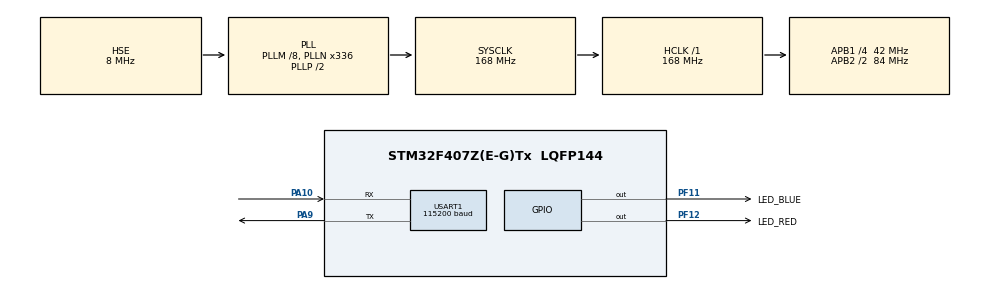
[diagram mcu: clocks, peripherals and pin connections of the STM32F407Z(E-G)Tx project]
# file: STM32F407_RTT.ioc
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Mcu.Family=STM32F4
Mcu.Name=STM32F407Z(E-G)Tx
Mcu.Package=LQFP144
NVIC.PriorityGroup=NVIC_PRIORITYGROUP_4
PA10.GPIO_PuPd=GPIO_PULLUP
PA10.Mode=Asynchronous
PA10.Signal=USART1_RX
PA13.Mode=Serial_Wire
PA13.Signal=SYS_JTMS-SWDIO
PA14.Mode=Serial_Wire
PA14.Signal=SYS_JTCK-SWCLK
PA9.GPIO_PuPd=GPIO_PULLUP
PA9.Mode=Asynchronous
PA9.Signal=USART1_TX
PC14-OSC32_IN.Mode=LSE-External-Oscillator
PC14-OSC32_IN.Signal=RCC_OSC32_IN
PC15-OSC32_OUT.Mode=LSE-External-Oscillator
PC15-OSC32_OUT.Signal=RCC_OSC32_OUT
PH0-OSC_IN.Mode=HSE-External-Oscillator
PH0-OSC_IN.Signal=RCC_OSC_IN
PH1-OSC_OUT.Mode=HSE-External-Oscillator
PH1-OSC_OUT.Signal=RCC_OSC_OUT
PF11.GPIO_Label=LED_BLUE
PF11.Signal=GPIO_Output
PF12.GPIO_Label=LED_RED
PF12.Signal=GPIO_Output
ProjectManager.HeapSize=0x200
ProjectManager.StackSize=0x400
ProjectManager.TargetToolchain=CMake
RCC.48MHZClocksFreq_Value=48000000
RCC.AHBFreq_Value=168000000
RCC.APB1CLKDivider=RCC_HCLK_DIV4
RCC.APB1Freq_Value=42000000
RCC.APB1TimFreq_Value=84000000
RCC.APB2CLKDivider=RCC_HCLK_DIV2
RCC.APB2Freq_Value=84000000
RCC.APB2TimFreq_Value=168000000
RCC.CortexFreq_Value=168000000
RCC.HCLKFreq_Value=168000000
RCC.HSE_VALUE=8000000
RCC.HSI_VALUE=16000000
RCC.PLLM=8
RCC.PLLN=336
RCC.PLLQ=7
RCC.PLLSourceVirtual=RCC_PLLSOURCE_HSE
RCC.SYSCLKFreq_VALUE=168000000
RCC.SYSCLKSource=RCC_SYSCLKSOURCE_PLLCLK
RCC.VCOOutputFreq_Value=336000000
USART1.BaudRate=115200
USART1.VirtualMode=VM_ASYNC
board=custom

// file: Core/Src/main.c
/* USER CODE BEGIN Header */
/**
  ******************************************************************************
  * @file           : main.c
  * @brief          : Main program body
  *                 中文说明：工程入口。依次完成 HAL 初始化、系统时钟配置和
  *                 基础外设（GPIO/USART1）初始化，随后调用 rtthread_startup()
  *                 把执行权交给 RT-Thread；业务逻辑在 lvgl/board/tshell 线程中
  *                 运行（见 Applications/runtime/app_tasks.c）。
  ******************************************************************************
  * @attention
  *
  * Copyright (c) 2026 STMicroelectronics.
  * All rights reserved.
  *
  * This software is licensed under terms that can be found in the LICENSE file
  * in the root directory of this software component.
  * If no LICENSE file comes with this software, it is provided AS-IS.
  *
  ******************************************************************************
  */
/* USER CODE END Header */
#include "main.h"
#include "gpio.h"
#include "usart.h"

/* USER CODE BEGIN Includes */
#include "board.h"
/* USER CODE END Includes */

void SystemClock_Config(void);

int main(void)
{

  /* MCU Configuration--------------------------------------------------------*/

  /*
   * 第 1 步：初始化 STM32 HAL。
   * HAL_Init() 会复位 HAL 的软件状态、配置 Flash 访问和 1 ms SysTick。
   * RT-Thread 启动后，SysTick 中断还会继续为操作系统提供系统节拍。
   */
  HAL_Init();

  /*
   * 第 2 步：配置系统时钟。
   * 当前使用板载 8 MHz HSE，经 PLL 倍频到 168 MHz：
   *   SYSCLK/HCLK = 168 MHz，APB1 = 42 MHz，APB2 = 84 MHz。
   * 时钟参数由 STM32CubeMX 管理，以后应在 .ioc 中修改后重新生成。
   */
  SystemClock_Config();

  /*
   * 第 3 步：只初始化启动 RTOS 前必须可用的基础外设。
   * GPIO 包含板载 LED 等基础管脚；USART1 是 ST-LINK 虚拟串口，参数为
   * 115200-8-N-1。LCD、按键和传感器由各自 BSP/应用线程稍后初始化。
   */
  MX_GPIO_Init();
  MX_USART1_UART_Init();
  /* USER CODE BEGIN 2 */
  /*
   * 第 4 步：把执行权交给 RT-Thread。
   * rtthread_startup() 初始化内核对象、创建 idle 线程并调用
   * rt_application_init() 创建本工程的 lvgl、board、tshell 线程。
   * 调度器启动成功后，本函数通常不会再继续向下执行。
   */
  rtthread_startup();
  /* USER CODE END 2 */

  /* Infinite loop */
  /* USER CODE BEGIN WHILE */
  while (1)
  {
    /*
     * 安全兜底循环：正常运行时不会到达这里。
     * 业务代码不要放在此处，应创建 RT-Thread 线程并使用延时/IPC 让出 CPU。
     */
    /* USER CODE END WHILE */

  }
}

void SystemClock_Config(void)
{
  RCC_OscInitTypeDef RCC_OscInitStruct = {0};
  RCC_ClkInitTypeDef RCC_ClkInitStruct = {0};

  /** Configure the main internal regulator output voltage
  */
  __HAL_RCC_PWR_CLK_ENABLE();
  __HAL_PWR_VOLTAGESCALING_CONFIG(PWR_REGULATOR_VOLTAGE_SCALE1);

  /** Initializes the RCC Oscillators according to the specified parameters
  * in the RCC_OscInitTypeDef structure.
  */
  RCC_OscInitStruct.OscillatorType = RCC_OSCILLATORTYPE_HSE;
  RCC_OscInitStruct.HSEState = RCC_HSE_ON;
  RCC_OscInitStruct.PLL.PLLState = RCC_PLL_ON;
  RCC_OscInitStruct.PLL.PLLSource = RCC_PLLSOURCE_HSE;
  RCC_OscInitStruct.PLL.PLLM = 8;
  RCC_OscInitStruct.PLL.PLLN = 336;
  RCC_OscInitStruct.PLL.PLLP = RCC_PLLP_DIV2;
  RCC_OscInitStruct.PLL.PLLQ = 7;
  if (HAL_RCC_OscConfig(&RCC_OscInitStruct) != HAL_OK)
  {
    Error_Handler();
  }

  /** Initializes the CPU, AHB and APB buses clocks
  */
  RCC_ClkInitStruct.ClockType = RCC_CLOCKTYPE_HCLK|RCC_CLOCKTYPE_SYSCLK
                              |RCC_CLOCKTYPE_PCLK1|RCC_CLOCKTYPE_PCLK2;
  RCC_ClkInitStruct.SYSCLKSource = RCC_SYSCLKSOURCE_PLLCLK;
  RCC_ClkInitStruct.AHBCLKDivider = RCC_SYSCLK_DIV1;
  RCC_ClkInitStruct.APB1CLKDivider = RCC_HCLK_DIV4;
  RCC_ClkInitStruct.APB2CLKDivider = RCC_HCLK_DIV2;

  if (HAL_RCC_ClockConfig(&RCC_ClkInitStruct, FLASH_LATENCY_5) != HAL_OK)
  {
    Error_Handler();
  }
}

void Error_Handler(void)
{
  /* USER CODE BEGIN Error_Handler_Debug */
  /* User can add his own implementation to report the HAL error return state */
  /* 出错时先关中断再原地停住：调试器断在此处即可回溯是哪个 HAL 调用失败。 */
  __disable_irq();
  while (1)
  {
  }
  /* USER CODE END Error_Handler_Debug */
}
